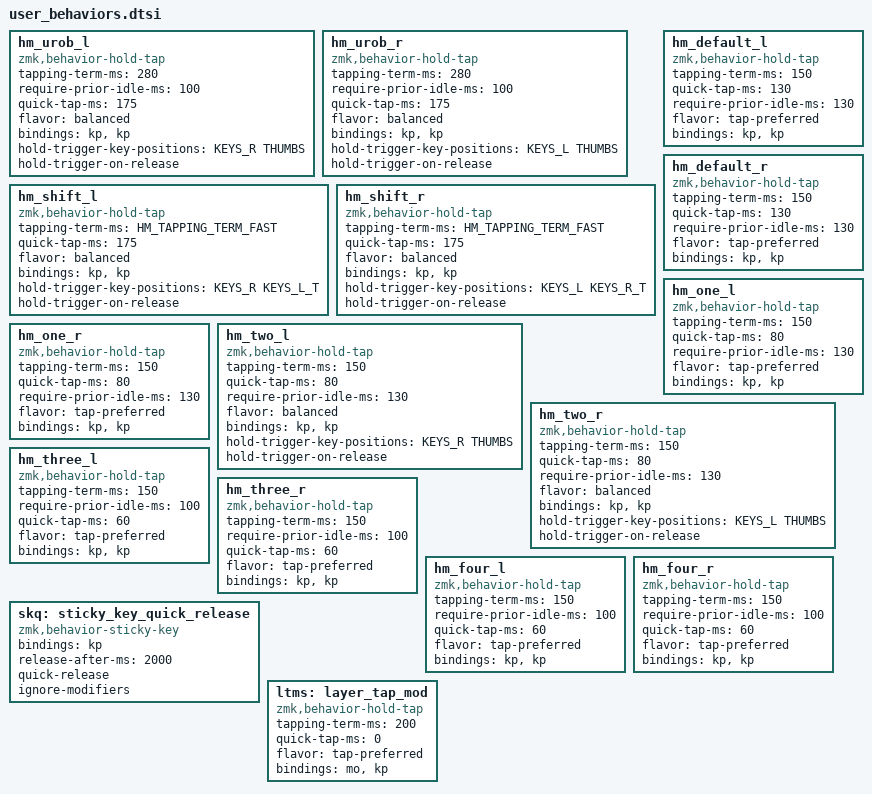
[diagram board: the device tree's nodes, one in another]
#include "../zmk-nodefree-config/keypos_def/keypos_34keys.h"
#define KEYS_L LT0 LT1 LT2 LT3 LT4 LM0 LM1 LM2 LM3 LM4 LB0 LB1 LB2 LB3 LB4  // left-hand keys
#define KEYS_R RT0 RT1 RT2 RT3 RT4 RM0 RM1 RM2 RM3 RM4 RB0 RB1 RB2 RB3 RB4  // right-hand keys
#define KEYS_T LH1 LH0 RH0 RH1  // tHumb keys
#define KEYS_L_T LH1 LH0 
#define KEYS_R_T RH0 RH1

// Home row speed settings 
#define hms_base_low_resistance_keycaps 500
#define hms_base_high_resistance_keycaps 200
#define hms_base 500
#define HMS_VVSLO (hms_base + 300)


#define HM_TAPPING_TERM 300
#define HM_TAPPING_TERM_FAST 200


// DEFINE BEHAVIORS FOR HOME ROW MODS. AND THEN COPY THESE SETTIGNS TO THE HOMEROW MODS LABELED DEFAULT AND THE (1 - 4)

        // home row mods - urob
        hm_urob_l: hm_urob_l {   
                compatible = "zmk,behavior-hold-tap";
                #binding-cells = <2>;
                tapping-term-ms = <280>;
                require-prior-idle-ms = <100>;
                quick-tap-ms = <175>;
                flavor = "balanced"; // will trigger the hold behavior when the tapping-term-ms has expired or another key is pressed and released.
                bindings = <&kp>, <&kp>;
                hold-trigger-key-positions = <KEYS_R THUMBS>; // including this will automatically turn on positional hold-tap
                hold-trigger-on-release; // If set to true, the evaluation of hold-trigger-key-positions gets delayed until key release. Ths allows combining multiple modifiers when the next key is held, while still deciding the hold-tap in favor of a tap when the next key is tapped.
        };
        hm_urob_r: hm_urob_r {   
                compatible = "zmk,behavior-hold-tap";
                #binding-cells = <2>;
                tapping-term-ms = <280>;
                require-prior-idle-ms = <100>;
                quick-tap-ms = <175>;
                flavor = "balanced";
                bindings = <&kp>, <&kp>;
                hold-trigger-key-positions = <KEYS_L THUMBS>;
                hold-trigger-on-release;
        };

        // Positional Homerow mods for shift
        // Use faster tapping term and disable some features that may
        // cause false negatives.
        hm_shift_l: hm_shift_l {
                compatible = "zmk,behavior-hold-tap";
                #binding-cells = <2>;
                tapping-term-ms = <HM_TAPPING_TERM_FAST>;
                // require-prior-idle-ms = <150>; // not used for shift
                quick-tap-ms = <175>;
                flavor = "balanced";
                bindings = <&kp>, <&kp>;
                hold-trigger-key-positions = <KEYS_R KEYS_L_T>;
                hold-trigger-on-release;
        };

        hm_shift_r: hm_shift_r {
                compatible = "zmk,behavior-hold-tap";
                #binding-cells = <2>;
                tapping-term-ms = <HM_TAPPING_TERM_FAST>;
                // require-prior-idle-ms = <150>;
                quick-tap-ms = <175>;
                flavor = "balanced";
                bindings = <&kp>, <&kp>;
                hold-trigger-key-positions = <KEYS_L KEYS_R_T>;
                hold-trigger-on-release;
        };


// tapping-term-ms // 2024-08-07 had 150 
// quick-tap-ms // 2024-08-07 had 140
// require-prior-idle-ms // 2024-08-07 had 140
// LAYER DEFAULT
hm_default_l: hm_default_l {
        compatible = "zmk,behavior-hold-tap";
        #binding-cells = <2>;
        // for 'tap-preferred': time to trigger the hold behavior.
        tapping-term-ms = <150>;
        // if you press a hold-tap within quick-tap-ms of the first press it will always trigger 
        // the tap behavior.
        // AKA - Tap twice within this period (in milliseconds) to trigger a tap, even when held
        quick-tap-ms = <130>;
        // like quick-tap-ms, however only apply for non-modifier key pressed before it.
        // Effectively disables hold-tap when typing quickly.
        // Recommended:  As a rule of thumb, you want to set it to at least 10500/x 
        // where x is your (relaxed) WPM for English prose.
        // {10,500/80=131}
        require-prior-idle-ms = <130>;
        flavor = "tap-preferred";
        bindings = <&kp>, <&kp>;
};
hm_default_r: hm_default_r {
        compatible = "zmk,behavior-hold-tap";
        #binding-cells = <2>;
        tapping-term-ms = <150>;
        quick-tap-ms = <130>;
        require-prior-idle-ms = <130>;
        flavor = "tap-preferred";
        bindings = <&kp>, <&kp>;
};

// LAYER HOME ROW MODS (NUMBERED)
// hm mod 1 - layer 1
hm_one_l: hm_one_l {   
        compatible = "zmk,behavior-hold-tap";
        #binding-cells = <2>;
        tapping-term-ms = <150>; // how long to hold to trigger hold
        quick-tap-ms = <80>; // from 60 to 80 2023-11-28 - want to reduce accidental holds
        require-prior-idle-ms = <130>; // outputs tap if within this time for hold-tap keys
        // this is like require but 
        flavor = "tap-preferred";
        bindings = <&kp>, <&kp>;
};
hm_one_r: hm_one_r {   
        compatible = "zmk,behavior-hold-tap";
        #binding-cells = <2>;
        tapping-term-ms = <150>;
        quick-tap-ms = <80>; // from 60 to 80 2023-11-28 - want to reduce accidental holds
        require-prior-idle-ms = <130>;
        flavor = "tap-preferred";
        bindings = <&kp>, <&kp>;
};

// hm mod 2 - layer 2
hm_two_l: hm_two_l {   
        compatible = "zmk,behavior-hold-tap";
        #binding-cells = <2>;
        tapping-term-ms = <150>;
        quick-tap-ms = <80>;
        require-prior-idle-ms = <130>;
        flavor = "balanced"; // will trigger the hold behavior when the tapping-term-ms has expired or another key is pressed and released.
        bindings = <&kp>, <&kp>;
        hold-trigger-key-positions = <KEYS_R THUMBS>; // including this will automatically turn on positional hold-tap
        hold-trigger-on-release; // If set to true, the evaluation of hold-trigger-key-positions gets delayed until key release. Ths allows combining multiple modifiers when the next key is held, while still deciding the hold-tap in favor of a tap when the next key is tapped.
};
hm_two_r: hm_two_r {   
        compatible = "zmk,behavior-hold-tap";
        #binding-cells = <2>;
        tapping-term-ms = <150>;
        quick-tap-ms = <80>;
        require-prior-idle-ms = <130>;
        flavor = "balanced";
        bindings = <&kp>, <&kp>;
        hold-trigger-key-positions = <KEYS_L THUMBS>;
        hold-trigger-on-release;
};

// hm mod 3 - layer 3
hm_three_l: hm_three_l {
        compatible = "zmk,behavior-hold-tap";
        #binding-cells = <2>;
        tapping-term-ms = <150>;
        require-prior-idle-ms = <100>;
        quick-tap-ms = <60>;
        flavor = "tap-preferred";
        bindings = <&kp>, <&kp>;
};
hm_three_r: hm_three_r {   
        compatible = "zmk,behavior-hold-tap";
        #binding-cells = <2>;
        tapping-term-ms = <150>;
        require-prior-idle-ms = <100>;
        quick-tap-ms = <60>;
        flavor = "tap-preferred";
        bindings = <&kp>, <&kp>;
};

// hm mod 4 - layer 4
// not many home row mods
hm_four_l: hm_four_l {
        compatible = "zmk,behavior-hold-tap";
        #binding-cells = <2>;
        tapping-term-ms = <150>;
        require-prior-idle-ms = <100>;
        quick-tap-ms = <60>;
        flavor = "tap-preferred";
        bindings = <&kp>, <&kp>;
};
hm_four_r: hm_four_r {   
        compatible = "zmk,behavior-hold-tap";
        #binding-cells = <2>;
        tapping-term-ms = <150>;
        require-prior-idle-ms = <100>;
        quick-tap-ms = <60>;
        flavor = "tap-preferred";
        bindings = <&kp>, <&kp>;
};


// KEYS
skq: sticky_key_quick_release {
        compatible = "zmk,behavior-sticky-key";
        #binding-cells = <1>;
        bindings = <&kp>;
        release-after-ms = <2000>;
        quick-release;
        ignore-modifiers;
};

// layer settings 
ltms: layer_tap_mod {
        compatible = "zmk,behavior-hold-tap";
        #binding-cells = <2>;
        tapping-term-ms = <200>;
        quick-tap-ms = <0>;
        flavor = "tap-preferred";
        bindings = <&mo>, <&kp>;
};

